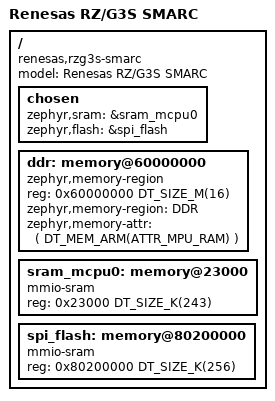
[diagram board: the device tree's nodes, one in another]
/*
 * Copyright (c) 2024 EPAM Systems
 * Copyright (c) 2024 Renesas Electronics Corporation
 * SPDX-License-Identifier: Apache-2.0
 */

/dts-v1/;

#include <freq.h>
#include <zephyr/dt-bindings/memory-attr/memory-attr-arm.h>

#include <arm/renesas/rz/rzg/r9a08g045.dtsi>

/ {
	model = "Renesas RZ/G3S SMARC";
	compatible = "renesas,rzg3s-smarc";

	chosen {
		zephyr,sram = &sram_mcpu0;
		zephyr,flash = &spi_flash;
	};

	ddr: memory@60000000 {
		compatible ="zephyr,memory-region", "mmio-sram";
		reg = <0x60000000 DT_SIZE_M(16)>;
		zephyr,memory-region = "DDR";
		zephyr,memory-attr = <( DT_MEM_ARM(ATTR_MPU_RAM) )>;
	};

	sram_mcpu0: memory@23000 {
		compatible = "mmio-sram";
		reg = <0x23000 DT_SIZE_K(243)>;
	};

	/*
	 * This node is defined to enable west flash support.
	 * The base addr and size depends on ATF-F configuration, which is running on Cortex-A55 and
	 * loading Zephyr app from xSPI flash.
	 */
	spi_flash: memory@80200000 {
		compatible = "mmio-sram";
		reg = <0x80200000 DT_SIZE_K(256)>;
	};

};
